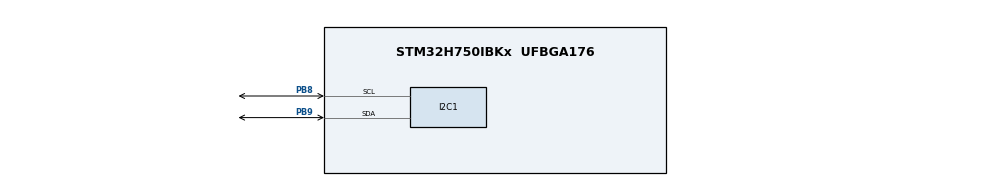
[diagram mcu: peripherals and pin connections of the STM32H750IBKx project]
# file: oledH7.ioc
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Mcu.Family=STM32H7
Mcu.Name=STM32H750IBKx
Mcu.Package=UFBGA176
NVIC.PriorityGroup=NVIC_PRIORITYGROUP_4
PB8.Mode=I2C
PB8.Signal=I2C1_SCL
PB9.Mode=I2C
PB9.Signal=I2C1_SDA
PC14-OSC32_IN\ (OSC32_IN).Mode=LSE-External-Oscillator
PC14-OSC32_IN\ (OSC32_IN).Signal=RCC_OSC32_IN
PC15-OSC32_OUT\ (OSC32_OUT).Mode=LSE-External-Oscillator
PC15-OSC32_OUT\ (OSC32_OUT).Signal=RCC_OSC32_OUT
PH0-OSC_IN\ (PH0).Mode=HSE-External-Oscillator
PH0-OSC_IN\ (PH0).Signal=RCC_OSC_IN
PH1-OSC_OUT\ (PH1).Mode=HSE-External-Oscillator
PH1-OSC_OUT\ (PH1).Signal=RCC_OSC_OUT
ProjectManager.HeapSize=0x200
ProjectManager.StackSize=0x400
ProjectManager.TargetToolchain=STM32CubeIDE
RCC.ADCFreq_Value=50390625
RCC.APB1Freq_Value=111718750
RCC.APB2Freq_Value=111718750
RCC.APB3Freq_Value=111718750
RCC.APB4Freq_Value=111718750
RCC.CECEnable-ClockTree=true
RCC.CortexFreq_Value=446875000
RCC.D1PPRE=RCC_APB3_DIV2
RCC.D2PPRE1=RCC_APB1_DIV2
RCC.D2PPRE2=RCC_APB2_DIV2
RCC.D3PPRE=RCC_APB4_DIV2
RCC.DIVM1=4
RCC.DIVN1=143
RCC.HCLKFreq_Value=223437500
RCC.HPRE=RCC_HCLK_DIV2
RCC.PLL1_VCI_Range-AdvancedSettings=RCC_PLL1VCIRANGE_0
RCC.PLL2FRACN=0
RCC.PLL2_VCO_SEL-AdvancedSettings=RCC_PLL2VCOWIDE
RCC.PLL3FRACN=0
RCC.PLLFRACN=0
RCC.PLLSourceVirtual=RCC_PLLSOURCE_HSE
RCC.SYSCLKFreq_VALUE=446875000
RCC.SYSCLKSource=RCC_SYSCLKSOURCE_PLLCLK
RCC.USBFreq_Value=446875000
board=custom

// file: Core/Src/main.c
/* USER CODE BEGIN Header */
/**
  ******************************************************************************
  * @file           : main.c
  * @brief          : Main program body
  ******************************************************************************
  * @attention
  *
  * <h2><center>&copy; Copyright (c) 2020 STMicroelectronics.
  * All rights reserved.</center></h2>
  *
  * This software component is licensed by ST under BSD 3-Clause license,
  * the "License"; You may not use this file except in compliance with the
  * License. You may obtain a copy of the License at:
  *                        opensource.org/licenses/BSD-3-Clause
  *
  ******************************************************************************
  */
/* USER CODE END Header */
#include "main.h"

#include "fonts.h"
#include "ssd1306.h"

I2C_HandleTypeDef hi2c1;

void SystemClock_Config(void);
static void MX_GPIO_Init(void);
static void MX_I2C1_Init(void);

int main(void)
{

  /* MCU Configuration--------------------------------------------------------*/

  /* Reset of all peripherals, Initializes the Flash interface and the Systick. */
  HAL_Init();

  /* Configure the system clock */
  SystemClock_Config();

  /* Initialize all configured peripherals */
  MX_GPIO_Init();
  MX_I2C1_Init();
  /* USER CODE BEGIN 2 */

  SSD1306_Init();

  SSD1306_GotoXY (1,0);
  SSD1306_Puts ("HELLO", &Font_7x10, 1);
  SSD1306_GotoXY (10, 30);
  SSD1306_Puts ("  World :)", &Font_7x10, 1);
  SSD1306_UpdateScreen(); //display

  /* USER CODE END 2 */

  /* Infinite loop */
  while (1)
  {

  }
}

void SystemClock_Config(void)
{
  RCC_OscInitTypeDef RCC_OscInitStruct = {0};
  RCC_ClkInitTypeDef RCC_ClkInitStruct = {0};
  RCC_PeriphCLKInitTypeDef PeriphClkInitStruct = {0};

  /** Supply configuration update enable
  */
  HAL_PWREx_ConfigSupply(PWR_LDO_SUPPLY);
  /** Configure the main internal regulator output voltage
  */
  __HAL_PWR_VOLTAGESCALING_CONFIG(PWR_REGULATOR_VOLTAGE_SCALE0);

  while(!__HAL_PWR_GET_FLAG(PWR_FLAG_VOSRDY)) {}
  /** Initializes the RCC Oscillators according to the specified parameters
  * in the RCC_OscInitTypeDef structure.
  */
  RCC_OscInitStruct.OscillatorType = RCC_OSCILLATORTYPE_HSE;
  RCC_OscInitStruct.HSEState = RCC_HSE_ON;
  RCC_OscInitStruct.PLL.PLLState = RCC_PLL_ON;
  RCC_OscInitStruct.PLL.PLLSource = RCC_PLLSOURCE_HSE;
  RCC_OscInitStruct.PLL.PLLM = 4;
  RCC_OscInitStruct.PLL.PLLN = 143;
  RCC_OscInitStruct.PLL.PLLP = 2;
  RCC_OscInitStruct.PLL.PLLQ = 2;
  RCC_OscInitStruct.PLL.PLLR = 2;
  RCC_OscInitStruct.PLL.PLLRGE = RCC_PLL1VCIRANGE_2;
  RCC_OscInitStruct.PLL.PLLVCOSEL = RCC_PLL1VCOWIDE;
  RCC_OscInitStruct.PLL.PLLFRACN = 0;
  if (HAL_RCC_OscConfig(&RCC_OscInitStruct) != HAL_OK)
  {
    Error_Handler();
  }
  /** Initializes the CPU, AHB and APB buses clocks
  */
  RCC_ClkInitStruct.ClockType = RCC_CLOCKTYPE_HCLK|RCC_CLOCKTYPE_SYSCLK
                              |RCC_CLOCKTYPE_PCLK1|RCC_CLOCKTYPE_PCLK2
                              |RCC_CLOCKTYPE_D3PCLK1|RCC_CLOCKTYPE_D1PCLK1;
  RCC_ClkInitStruct.SYSCLKSource = RCC_SYSCLKSOURCE_PLLCLK;
  RCC_ClkInitStruct.SYSCLKDivider = RCC_SYSCLK_DIV1;
  RCC_ClkInitStruct.AHBCLKDivider = RCC_HCLK_DIV2;
  RCC_ClkInitStruct.APB3CLKDivider = RCC_APB3_DIV2;
  RCC_ClkInitStruct.APB1CLKDivider = RCC_APB1_DIV2;
  RCC_ClkInitStruct.APB2CLKDivider = RCC_APB2_DIV2;
  RCC_ClkInitStruct.APB4CLKDivider = RCC_APB4_DIV2;

  if (HAL_RCC_ClockConfig(&RCC_ClkInitStruct, FLASH_LATENCY_3) != HAL_OK)
  {
    Error_Handler();
  }
  PeriphClkInitStruct.PeriphClockSelection = RCC_PERIPHCLK_I2C1;
  PeriphClkInitStruct.I2c123ClockSelection = RCC_I2C123CLKSOURCE_D2PCLK1;
  if (HAL_RCCEx_PeriphCLKConfig(&PeriphClkInitStruct) != HAL_OK)
  {
    Error_Handler();
  }
}

static void MX_I2C1_Init(void)
{

  hi2c1.Instance = I2C1;
  hi2c1.Init.Timing = 0x10707DBC;
  hi2c1.Init.OwnAddress1 = 0;
  hi2c1.Init.AddressingMode = I2C_ADDRESSINGMODE_7BIT;
  hi2c1.Init.DualAddressMode = I2C_DUALADDRESS_DISABLE;
  hi2c1.Init.OwnAddress2 = 0;
  hi2c1.Init.OwnAddress2Masks = I2C_OA2_NOMASK;
  hi2c1.Init.GeneralCallMode = I2C_GENERALCALL_DISABLE;
  hi2c1.Init.NoStretchMode = I2C_NOSTRETCH_DISABLE;
  if (HAL_I2C_Init(&hi2c1) != HAL_OK)
  {
    Error_Handler();
  }
  /** Configure Analogue filter
  */
  if (HAL_I2CEx_ConfigAnalogFilter(&hi2c1, I2C_ANALOGFILTER_ENABLE) != HAL_OK)
  {
    Error_Handler();
  }
  /** Configure Digital filter
  */
  if (HAL_I2CEx_ConfigDigitalFilter(&hi2c1, 0) != HAL_OK)
  {
    Error_Handler();
  }

}

static void MX_GPIO_Init(void)
{

  /* GPIO Ports Clock Enable */
  __HAL_RCC_GPIOB_CLK_ENABLE();
  __HAL_RCC_GPIOC_CLK_ENABLE();
  __HAL_RCC_GPIOH_CLK_ENABLE();

}

void Error_Handler(void)
{
}

/************************ (C) COPYRIGHT STMicroelectronics *****END OF FILE****/
